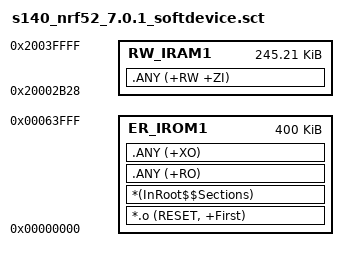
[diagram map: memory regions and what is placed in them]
; *************************************************************
; *** Scatter-Loading Description File generated by uVision ***
; *************************************************************

LR_IROM1 0x00000000 0x00064000  {    ; load region size_region
  ER_IROM1 0x00000000 0x00064000  {  ; load address = execution address
   *.o (RESET, +First)
   *(InRoot$$Sections)
   .ANY (+RO)
   .ANY (+XO)
  }
  RW_IRAM1 0x20002B28 0x0003D4D8  {  ; RW data
   .ANY (+RW +ZI)
  }
}

